VERSION ""

NS_ :

BS_:

BU_:
VAL_TABLE_ OdometerRoutineRequestToHMI 7 "Reserved" 6 "Reserved" 5 "Reserved" 4 "ResetBackupODM_Storage " 3 "ClearNotActiveODM_DTC " 2 "ReadOdometerDTC" 1 "WriteDCUOdometerValueToHMI" 0 "RetrieveOdometerBackupValue" ;
VAL_TABLE_ ODM_StatusFlags 3 "Reserved" 2 "NA" 1 "Fault" 0 "NoFault" ;

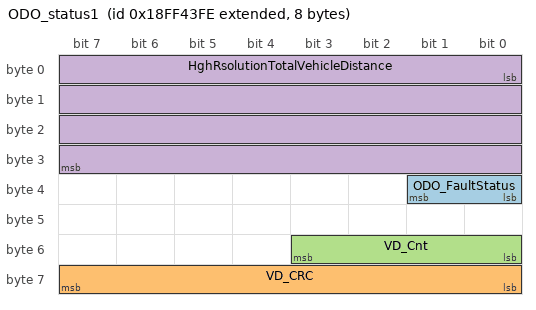
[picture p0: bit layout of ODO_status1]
BO_ 2566865918 ODO_status1: 8 Vector__XXX
 SG_ ODO_FaultStatus : 32|2@1+ (1,0) [0|3] "" Vector__XXX
 SG_ VD_CRC : 56|8@1+ (1,0) [0|255] "" Vector__XXX
 SG_ VD_Cnt : 48|4@1+ (1,0) [0|15] "" Vector__XXX
 SG_ HghRsolutionTotalVehicleDistance : 0|32@1+ (1,0) [0|4294967295] "m" Vector__XXX

CM_ SG_ 2566865918 HghRsolutionTotalVehicleDistance "Distance traveled during all or part of a journey.";
BA_DEF_ SG_  "SigType" ENUM  "Default","Range","RangeSigned","ASCII","Discrete","Control","ReferencePGN","DTC","StringDelimiter","StringLength","StringLengthControl","MessageCounter","MessageChecksum";
BA_DEF_ SG_  "GenSigEVName" STRING ;
BA_DEF_ SG_  "GenSigILSupport" ENUM  "No","Yes";
BA_DEF_ SG_  "GenSigSendType" ENUM  "Cyclic","OnWrite","OnWriteWithRepetition","OnChange","OnChangeWithRepetition","IfActive","IfActiveWithRepetition","NoSigSendType";
BA_DEF_ BO_  "Producer" STRING ;
BA_DEF_ BO_  "GenMsgILSupport" ENUM  "No","Yes";
BA_DEF_ BU_  "NmStationAddress" INT 0 255;
BA_DEF_ BO_  "GenMsgSendType" ENUM  "cyclic","NotUsed","IfActive","NotUsed","NotUsed","NotUsed","NotUsed","NotUsed","noMsgSendType";
BA_DEF_ BO_  "GenMsgRequestable" INT 0 1;
BA_DEF_ BO_  "GenMsgCycleTime" INT 0 3600000;
BA_DEF_ SG_  "SPN" INT 0 524287;
BA_DEF_  "DBName" STRING ;
BA_DEF_  "BusType" STRING ;
BA_DEF_  "ProtocolType" STRING ;
BA_DEF_ BO_  "VFrameFormat" ENUM  "StandardCAN","ExtendedCAN","reserved","J1939PG";
BA_DEF_DEF_ "Producer" "DTS" ;
BA_DEF_DEF_  "SigType" "Default";
BA_DEF_DEF_  "GenSigEVName" "Env@Nodename_@Signame";
BA_DEF_DEF_  "GenSigILSupport" "Yes";
BA_DEF_DEF_  "GenSigSendType" "NoSigSendType";
BA_DEF_DEF_  "GenMsgILSupport" "Yes";
BA_DEF_DEF_  "NmStationAddress" 254;
BA_DEF_DEF_  "GenMsgSendType" "noMsgSendType";
BA_DEF_DEF_  "GenMsgRequestable" 1;
BA_DEF_DEF_  "GenMsgCycleTime" 0;
BA_DEF_DEF_  "SPN" 0;
BA_DEF_DEF_  "DBName" "";
BA_DEF_DEF_  "BusType" "CAN";
BA_DEF_DEF_  "ProtocolType" "J1939";
BA_DEF_DEF_  "VFrameFormat" "J1939PG";
BA_ "DBName" "J1939Template";
BA_ "GenMsgCycleTime" BO_ 2566865918 1000;
BA_ "GenMsgSendType" BO_ 2566865918 0;
BA_ "SigType" SG_ 2566865918 VD_CRC 12;
BA_ "SigType" SG_ 2566865918 VD_Cnt 11;
BA_ "SPN" SG_ 2566865918 HghRsolutionTotalVehicleDistance 918;
BA_ "SigType" SG_ 2566865918 HghRsolutionTotalVehicleDistance 1;
VAL_ 2566865918 ODO_FaultStatus 3 "Reserved" 2 "NA" 1 "Fault" 0 "NoFault" ;
